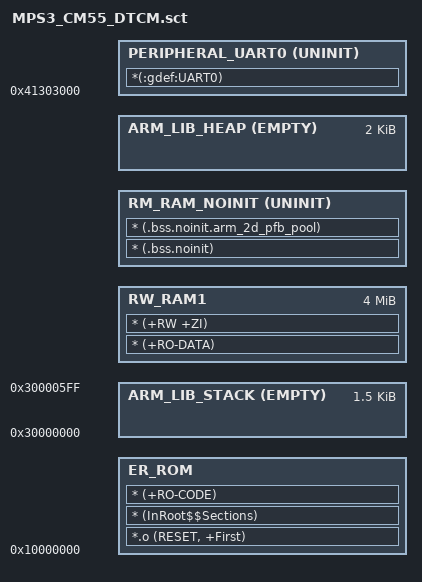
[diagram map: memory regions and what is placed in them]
#! armclang -E --target=arm-arm-none-eabi -mcpu=cortex-m33 -xc
; command above MUST be in first line (no comment above!)

/*
;-------- <<< Use Configuration Wizard in Context Menu >>> -------------------
*/

/*--------------------- Flash Configuration ----------------------------------
; <h> Flash Configuration
;   <o0> Flash Base Address <0x0-0xFFFFFFFF:8>
;   <o1> Flash Size (in Bytes) <0x0-0xFFFFFFFF:8>
; </h>
 *----------------------------------------------------------------------------*/
#define __ROM_BASE     0x10000000
#define __ROM_SIZE     0x00300000

/*--------------------- Embedded RAM Configuration ---------------------------
; <h> RAM Configuration
;   <o0> RAM1 Base Address    <0x0-0xFFFFFFFF:8>
;   <o1> RAM1 Size (in Bytes) <0x0-0xFFFFFFFF:8>
; </h>
 *----------------------------------------------------------------------------*/
#define __RAM1_BASE     0x30000000
#define __RAM1_SIZE     0x00400000


/*--------------------- Embedded RAM Configuration ---------------------------
; <h> RAM Configuration
;   <o0> RAM2 Base Address    <0x0-0xFFFFFFFF:8>
;   <o1> RAM2 Size (in Bytes) <0x0-0xFFFFFFFF:8>
; </h>
 *----------------------------------------------------------------------------*/
#define __RAM2_BASE     0x70000000
#define __RAM2_SIZE     0x10000000
//#define __HEAP_SIZE     0x10000000
//#define __HEAP_BASE     __RAM2_BASE

#define __HEAP_SIZE     0x00000800
#define __HEAP_BASE     +0

/*--------------------- Stack / Heap Configuration ---------------------------
; <h> Stack / Heap Configuration
;   <o0> Stack Size (in Bytes) <0x0-0xFFFFFFFF:8>
;   <o1> Heap Size (in Bytes) <0x0-0xFFFFFFFF:8>
; </h>
 *----------------------------------------------------------------------------*/
#define __STACK_SIZE    0x00000600

#define __RAM1_RW_SIZE 	(__RAM1_SIZE - __STACK_SIZE - __HEAP_SIZE)
//#define __RAM1_RW_SIZE 	(__RAM1_SIZE - __STACK_SIZE)

LR_ROM __ROM_BASE __ROM_SIZE  {                                                 ; load region size_region
    ER_ROM +0 {                                                                 ; load address = execution address
        *.o (RESET, +First)
        * (InRoot$$Sections)
        ;   *(Veneer$$CMSE)                                                     ; uncomment for secure applications
        * (+RO-CODE)
        ;   * (+XO)
    }

    ARM_LIB_STACK __RAM1_BASE ALIGN 8 EMPTY __STACK_SIZE {                      ; Reserve empty region for stack
    }

    RW_RAM1 +0 __RAM1_RW_SIZE {
        * (+RO-DATA)
        * (+RW +ZI)
    }

    RM_RAM_NOINIT +0 UNINIT {
        * (.bss.noinit)
        * (.bss.noinit.arm_2d_pfb_pool)
    }

    ARM_LIB_HEAP  __HEAP_BASE ALIGN 8 EMPTY __HEAP_SIZE  {                      ; Reserve empty region for heap
    }
  
    PERIPHERAL_UART0 0x41303000 UNINIT {
        *(:gdef:UART0)
    }
}

#if 0
LD_ROM_FFF __RAM2_BASE __RAM2_SIZE {
    FFF_MEM_CONTENT +0 {
        * (fff_mem_file)
    }
}
#endif

